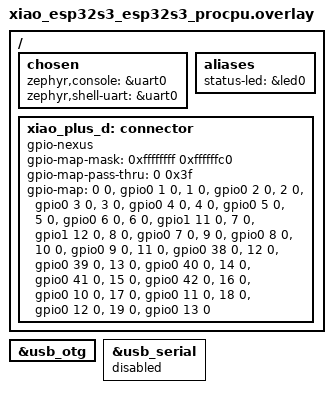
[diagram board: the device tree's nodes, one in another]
/ {
    chosen {
        zephyr,console = &uart0;
        zephyr,shell-uart = &uart0;
    };
};

/ {
    aliases {
        status-led = &led0;
    };
};

zephyr_udc0: &usb_otg {
    status = "okay";
};

&usb_serial {
    status = "disabled";
};

/ {
    xiao_plus_d: connector {
        compatible = "gpio-nexus";
        #gpio-cells = <2>;
        gpio-map-mask = <0xffffffff 0xffffffc0>;
        gpio-map-pass-thru = <0 0x3f>;
        gpio-map = <0 0 &gpio0 1 0>, /* D0 */
               <1 0 &gpio0 2 0>,     /* D1 */
               <2 0 &gpio0 3 0>,     /* D2 */
               <3 0 &gpio0 4 0>,     /* D3 */
               <4 0 &gpio0 5 0>,     /* D4 */
               <5 0 &gpio0 6 0>,     /* D5 */
               <6 0 &gpio1 11 0>,    /* D6 */
               <7 0 &gpio1 12 0>,    /* D7 */
               <8 0 &gpio0 7 0>,     /* D8 */
               <9 0 &gpio0 8 0>,     /* D9 */
               <10 0 &gpio0 9 0>,    /* D10 */
               <11 0 &gpio0 38 0>,    /* D0.5 */
               <12 0 &gpio0 39 0>,    /* D1.5 */
               <13 0 &gpio0 40 0>,    /* D2.5 */
               <14 0 &gpio0 41 0>,    /* D3.5 */
               <15 0 &gpio0 42 0>,    /* D4.5 */
               <16 0 &gpio0 10 0>,    /* D5.5 */
               <17 0 &gpio0 11 0>,    /* D7.5 */
               <18 0 &gpio0 12 0>,    /* D8.5 */
               <19 0 &gpio0 13 0>;    /* D9.5 */
    };
};
